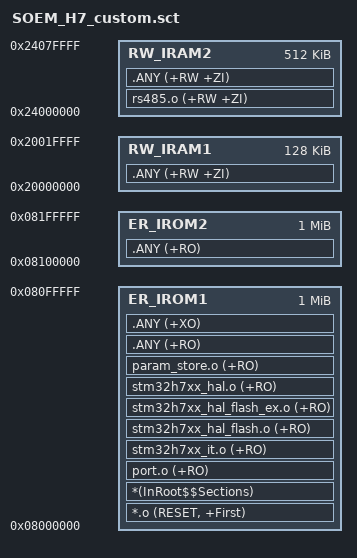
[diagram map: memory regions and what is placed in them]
; ******************************************************************
; *** Custom Scatter-Loading File                                 ***
; *** 关键模块锁定在 Bank1, 确保擦除 Bank2 时 SysTick/ISR/Flash    ***
; *** 驱动代码不会被阻塞                                          ***
; ******************************************************************

LR_IROM1 0x08000000 0x00100000  {    ; Bank1: 1MB
  ER_IROM1 0x08000000 0x00100000  {  ; Code in Bank1
   *.o (RESET, +First)
   *(InRoot$$Sections)
   ; === CRITICAL: 以下模块必须在 Bank1, 擦除 Bank2 时不能访问 Bank2 ===
   port.o (+RO)                    ; FreeRTOS: SysTick_Handler/PendSV_Handler/SVC_Handler
   stm32h7xx_it.o (+RO)            ; 中断处理: HardFault/BusFault/DebugMon
   stm32h7xx_hal_flash.o (+RO)     ; HAL Flash: FLASH_WaitForLastOperation
   stm32h7xx_hal_flash_ex.o (+RO)  ; HAL Flash Ex: FLASH_Erase_Sector/FLASH_MassErase
   stm32h7xx_hal.o (+RO)           ; HAL Base: HAL_GetTick/HAL_Delay
   param_store.o (+RO)             ; 参数存储: ParamSlot_EraseAndWrite
   .ANY (+RO)
   .ANY (+XO)
  }
  RW_IRAM1 0x20000000 0x00020000  {  ; DTCM: 128KB
   .ANY (+RW +ZI)
  }
  RW_IRAM2 0x24000000 0x00080000  {  ; AXI SRAM: 512KB (DMA accessible)
   rs485.o (+RW +ZI)            ; RS485 DMA buffers must NOT be in DTCM
   .ANY (+RW +ZI)
  }
}

LR_IROM2 0x08100000 0x00100000  {    ; Bank2: 1MB (剩余代码放置于此)
  ER_IROM2 0x08100000 0x00100000  {
   .ANY (+RO)
  }
}
